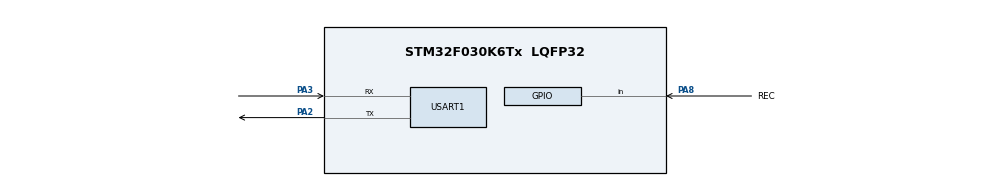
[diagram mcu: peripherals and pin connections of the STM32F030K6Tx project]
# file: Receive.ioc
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Mcu.Family=STM32F0
Mcu.Name=STM32F030K6Tx
Mcu.Package=LQFP32
NVIC.USART1_IRQn=true\:3\:0\:true\:false\:true\:true\:true
PA13.Mode=Serial_Wire
PA13.Signal=SYS_SWDIO
PA14.Mode=Serial_Wire
PA14.Signal=SYS_SWCLK
PA2.Mode=Asynchronous
PA2.Signal=USART1_TX
PA3.Mode=Asynchronous
PA3.Signal=USART1_RX
PA8.GPIO_Label=REC
PA8.Signal=GPIO_Input
ProjectManager.HeapSize=0x200
ProjectManager.StackSize=0x400
ProjectManager.TargetToolchain=MDK-ARM V5
TIM3.AutoReloadPreload=TIM_AUTORELOAD_PRELOAD_ENABLE
TIM3.Period=9999
TIM3.Prescaler=7
USART1.VirtualMode-Asynchronous=VM_ASYNC
VP_TIM3_VS_ClockSourceINT.Mode=Internal
board=custom

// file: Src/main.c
/* USER CODE BEGIN Header */
/**
  ******************************************************************************
  * @file           : main.c
  * @brief          : Main program body
  ******************************************************************************
  * @attention
  *
  * <h2><center>&copy; Copyright (c) 2019 STMicroelectronics.
  * All rights reserved.</center></h2>
  *
  * This software component is licensed by ST under BSD 3-Clause license,
  * the "License"; You may not use this file except in compliance with the
  * License. You may obtain a copy of the License at:
  *                        opensource.org/licenses/BSD-3-Clause
  *
  ******************************************************************************
  */
/* USER CODE END Header */

#include "main.h"

/* USER CODE BEGIN Includes */
#include "string.h"
/* USER CODE END Includes */

TIM_HandleTypeDef htim3;

UART_HandleTypeDef huart1;

/* USER CODE BEGIN PV */

uint16_t count;
uint32_t data;

uint16_t duration[300];
uint8_t err = 0;
uint8_t dataa[4];
/* USER CODE END PV */

void SystemClock_Config(void);
static void MX_GPIO_Init(void);
static void MX_TIM3_Init(void);
static void MX_USART1_UART_Init(void);
/* USER CODE BEGIN PFP */

void uDelay(const uint16_t d);

/* USER CODE END PFP */

int main(void)
{

  /* MCU Configuration--------------------------------------------------------*/

  /* Reset of all peripherals, Initializes the Flash interface and the Systick. */
  HAL_Init();

  /* Configure the system clock */
  SystemClock_Config();

  /* Initialize all configured peripherals */
  MX_GPIO_Init();
  MX_TIM3_Init();
  MX_USART1_UART_Init();

  /* Infinite loop */
  while (1)
  {

    /* USER CODE BEGIN 3 */

		/******Durations********/

		if (HAL_GPIO_ReadPin(GPIOA, GPIO_PIN_8))
		{
			TIM3->CNT = 0;
			uint16_t i = 0;
			while(i < 300)
			{
				while (HAL_GPIO_ReadPin (GPIOA, GPIO_PIN_8))
				{
						if (TIM3->CNT > 9500)
							err = 1;
				}
				duration[i] = TIM3->CNT;
				TIM3->CNT = 0;
				i++;
				if (err)
					break;

				while(!(HAL_GPIO_ReadPin (GPIOA, GPIO_PIN_8)))
				{
					if (TIM3->CNT > 9500)
							err = 1;
				}
				duration[i] = TIM3->CNT;
				TIM3->CNT = 0;
				i++;
				if (err)
					break;

			}
			err = 0;
			/* Serial print out */

		}

		/********End of Duration*********/

		/*for(uint8_t i=0;i<4;i++)
		{
		for(uint8_t j=0;j<8;j++)
		{
		dataa[i]|= data & (1UL << (31-j));
		}
		data=data &(1UL << (31-i*8));
	 }*/
		//we can only transmit 1byte at a time
		/*data1=data & 11111111000000000000000000000000;
		data2=data & 00000000111111110000000000000000;
		data3=data & 00000000000000001111111100000000;
		data4=data & 00000000000000000000000011111111;
		//transmitting from stm to the laptop serial terminal
		HAL_UART_transmit(&huart2 , *data1 , strlen(*data1) ,100);
		HAL_UART_transmit(&huart2 , *data2 , strlen(*data2) ,100);
		HAL_UART_transmit(&huart2 , *data3 , strlen(*data3) ,100);
		HAL_UART_transmit(&huart2 , *data4"\r\n" , strlen(*data4"\r\n") ,100);
		HAL_Delay(500);*/

		while (HAL_GPIO_ReadPin (GPIOA, GPIO_PIN_8));   // wait for the pin to go low
		while (!(HAL_GPIO_ReadPin (GPIOA, GPIO_PIN_8)));  // wait for the pin to go high.. 9ms LOW
		while (HAL_GPIO_ReadPin (GPIOA, GPIO_PIN_8));   // wait for the pin to go low
		for (int i=0; i<32; i++)
	  {
		  count=0;

		  while (!(HAL_GPIO_ReadPin (GPIOA, GPIO_PIN_8))); // wait for pin to go high.. this is 562.5us LOW

		  while ((HAL_GPIO_ReadPin (GPIOA, GPIO_PIN_8)))  // count the space length while the pin is high
		  {
			  count++;
			  uDelay(100);
		  }

		  if (count > 12) // if the space is more than 1.2 ms
		  {
			  data |= (1UL << (31-i));   // write 1
		  }

		  else data &= ~(1UL << (31-i));  // write 0
	  }

		HAL_UART_transmit(&huart1 , *data , strlen(*data) ,100);

		HAL_UART_transmit(&huart1 , *dataa[2] , strlen(dataa[2]) ,100);
		HAL_UART_transmit(&huart1 , *dataa[3] , strlen(dataa[3]) ,100);
		HAL_UART_transmit(&huart1 , *dataa[4]"\r\n" , strlen(dataa[4]), "\r\n" ,100);
		HAL_UART_transmit(&huart1 , "salam\r\n" , strlen("salam\r\n") ,100);
  }
  /* USER CODE END 3 */
}

void SystemClock_Config(void)
{
  RCC_OscInitTypeDef RCC_OscInitStruct = {0};
  RCC_ClkInitTypeDef RCC_ClkInitStruct = {0};
  RCC_PeriphCLKInitTypeDef PeriphClkInit = {0};

  /** Initializes the CPU, AHB and APB busses clocks
  */
  RCC_OscInitStruct.OscillatorType = RCC_OSCILLATORTYPE_HSI;
  RCC_OscInitStruct.HSIState = RCC_HSI_ON;
  RCC_OscInitStruct.HSICalibrationValue = RCC_HSICALIBRATION_DEFAULT;
  RCC_OscInitStruct.PLL.PLLState = RCC_PLL_NONE;
  if (HAL_RCC_OscConfig(&RCC_OscInitStruct) != HAL_OK)
  {
    Error_Handler();
  }
  /** Initializes the CPU, AHB and APB busses clocks
  */
  RCC_ClkInitStruct.ClockType = RCC_CLOCKTYPE_HCLK|RCC_CLOCKTYPE_SYSCLK
                              |RCC_CLOCKTYPE_PCLK1;
  RCC_ClkInitStruct.SYSCLKSource = RCC_SYSCLKSOURCE_HSI;
  RCC_ClkInitStruct.AHBCLKDivider = RCC_SYSCLK_DIV1;
  RCC_ClkInitStruct.APB1CLKDivider = RCC_HCLK_DIV1;

  if (HAL_RCC_ClockConfig(&RCC_ClkInitStruct, FLASH_LATENCY_0) != HAL_OK)
  {
    Error_Handler();
  }
  PeriphClkInit.PeriphClockSelection = RCC_PERIPHCLK_USART1;
  PeriphClkInit.Usart1ClockSelection = RCC_USART1CLKSOURCE_PCLK1;
  if (HAL_RCCEx_PeriphCLKConfig(&PeriphClkInit) != HAL_OK)
  {
    Error_Handler();
  }
}

static void MX_TIM3_Init(void)
{

  TIM_ClockConfigTypeDef sClockSourceConfig = {0};
  TIM_MasterConfigTypeDef sMasterConfig = {0};

  htim3.Instance = TIM3;
  htim3.Init.Prescaler = 7;
  htim3.Init.CounterMode = TIM_COUNTERMODE_UP;
  htim3.Init.Period = 9999;
  htim3.Init.ClockDivision = TIM_CLOCKDIVISION_DIV1;
  htim3.Init.AutoReloadPreload = TIM_AUTORELOAD_PRELOAD_ENABLE;
  if (HAL_TIM_Base_Init(&htim3) != HAL_OK)
  {
    Error_Handler();
  }
  sClockSourceConfig.ClockSource = TIM_CLOCKSOURCE_INTERNAL;
  if (HAL_TIM_ConfigClockSource(&htim3, &sClockSourceConfig) != HAL_OK)
  {
    Error_Handler();
  }
  sMasterConfig.MasterOutputTrigger = TIM_TRGO_RESET;
  sMasterConfig.MasterSlaveMode = TIM_MASTERSLAVEMODE_DISABLE;
  if (HAL_TIMEx_MasterConfigSynchronization(&htim3, &sMasterConfig) != HAL_OK)
  {
    Error_Handler();
  }

}

static void MX_USART1_UART_Init(void)
{

  huart1.Instance = USART1;
  huart1.Init.BaudRate = 38400;
  huart1.Init.WordLength = UART_WORDLENGTH_8B;
  huart1.Init.StopBits = UART_STOPBITS_1;
  huart1.Init.Parity = UART_PARITY_NONE;
  huart1.Init.Mode = UART_MODE_TX_RX;
  huart1.Init.HwFlowCtl = UART_HWCONTROL_NONE;
  huart1.Init.OverSampling = UART_OVERSAMPLING_16;
  huart1.Init.OneBitSampling = UART_ONE_BIT_SAMPLE_DISABLE;
  huart1.AdvancedInit.AdvFeatureInit = UART_ADVFEATURE_NO_INIT;
  if (HAL_UART_Init(&huart1) != HAL_OK)
  {
    Error_Handler();
  }

}

static void MX_GPIO_Init(void)
{
  GPIO_InitTypeDef GPIO_InitStruct = {0};

  /* GPIO Ports Clock Enable */
  __HAL_RCC_GPIOA_CLK_ENABLE();

  /*Configure GPIO pin : REC_Pin */
  GPIO_InitStruct.Pin = REC_Pin;
  GPIO_InitStruct.Mode = GPIO_MODE_INPUT;
  GPIO_InitStruct.Pull = GPIO_NOPULL;
  HAL_GPIO_Init(REC_GPIO_Port, &GPIO_InitStruct);

}

/* USER CODE BEGIN 4 */

void uDelay(const uint16_t d)
{
	TIM3->CNT = 0;
	while(TIM3->CNT < d);
}

/* USER CODE END 4 */

void Error_Handler(void)
{
}

/************************ (C) COPYRIGHT STMicroelectronics *****END OF FILE****/
